VERSION ""

NS_ :

BS_:

BU_: SENSOR_BOARD GATEWAY_NODE

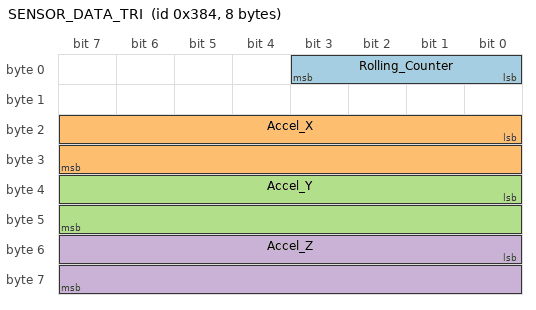
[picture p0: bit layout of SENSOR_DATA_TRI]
BO_ 900 SENSOR_DATA_TRI: 8 SENSOR_BOARD
 SG_ Rolling_Counter : 0|4@1+ (1,0) [0|15] "" GATEWAY_NODE
 SG_ Accel_X : 16|16@1- (0.01,0) [-327.68|327.67] "G" GATEWAY_NODE
 SG_ Accel_Y : 32|16@1- (0.01,0) [-327.68|327.67] "G" GATEWAY_NODE
 SG_ Accel_Z : 48|16@1- (0.01,0) [-327.68|327.67] "G" GATEWAY_NODE

BO_ 901 SENSOR_DATA_STRAIN: 8 SENSOR_BOARD
 SG_ Rolling_Counter : 0|4@1+ (1,0) [0|15] "" GATEWAY_NODE
 SG_ Strain_Value : 48|16@1- (0.01,0) [-327.68|327.67] "raw" GATEWAY_NODE

BO_ 902 SENSOR_DATA_UNIAXIAL: 8 SENSOR_BOARD
 SG_ Rolling_Counter : 0|4@1+ (1,0) [0|15] "" GATEWAY_NODE
 SG_ Uniaxial_G : 32|32@1- (0.001,0) [-2147483.648|2147483.647] "G" GATEWAY_NODE

BA_DEF_  "BusType" STRING ;
BA_DEF_DEF_  "BusType" "CAN";
